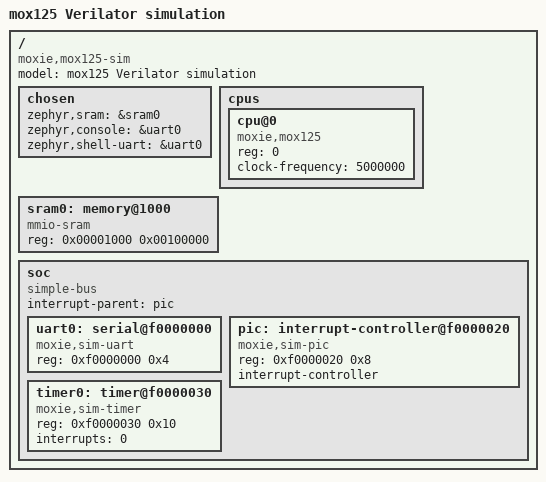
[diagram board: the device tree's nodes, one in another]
/*
 * Copyright (c) 2026 Anthony Green
 *
 * SPDX-License-Identifier: Apache-2.0
 */

/dts-v1/;

/ {
	#address-cells = <1>;
	#size-cells = <1>;
	model = "mox125 Verilator simulation";
	compatible = "moxie,mox125-sim";

	chosen {
		zephyr,sram = &sram0;
		zephyr,console = &uart0;
		zephyr,shell-uart = &uart0;
	};

	cpus {
		#address-cells = <1>;
		#size-cells = <0>;

		cpu@0 {
			device_type = "cpu";
			compatible = "moxie,mox125";
			reg = <0>;
			/*
			 * Nominal.  Simulated time is counted in clocks, and
			 * at this rate the default 100 ticks a second leaves
			 * the core 50,000 clocks of work between ticks.
			 */
			clock-frequency = <5000000>;
		};
	};

	/* The core starts executing at 0x1000. */
	sram0: memory@1000 {
		device_type = "memory";
		compatible = "mmio-sram";
		reg = <0x00001000 0x00100000>;
	};

	soc {
		#address-cells = <1>;
		#size-cells = <1>;
		compatible = "simple-bus";
		interrupt-parent = <&pic>;
		ranges;

		uart0: serial@f0000000 {
			compatible = "moxie,sim-uart";
			reg = <0xf0000000 0x4>;
			status = "okay";
		};

		pic: interrupt-controller@f0000020 {
			compatible = "moxie,sim-pic";
			reg = <0xf0000020 0x8>;
			interrupt-controller;
			#interrupt-cells = <1>;
		};

		timer0: timer@f0000030 {
			compatible = "moxie,sim-timer";
			reg = <0xf0000030 0x10>;
			interrupts = <0>;
		};
	};
};
